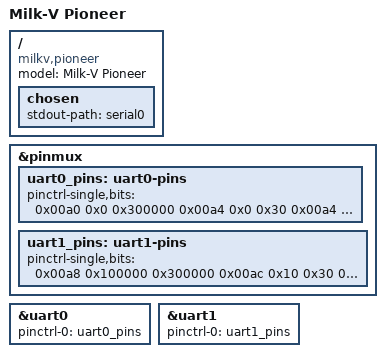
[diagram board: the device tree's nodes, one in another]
// SPDX-License-Identifier: GPL-2.0 OR MIT
/*
 * Copyright (C) 2022 Sophgo Technology Inc. All rights reserved.
 */

#include "sg2042.dtsi"

/ {
	model = "Milk-V Pioneer";
	compatible = "milkv,pioneer", "sophgo,sg2042";

	chosen {
		stdout-path = "serial0";
	};
};

&pinmux {
	status = "okay";

	uart0_pins: uart0-pins {
		pinctrl-single,bits = <
			/* UART0_TX */
			0x00a0 0x0 0x300000
			/* UART0_RX */
			0x00a4 0x0 0x30
			/* UART0_RTS */
			0x00a4 0x0 0x300000
			/* UART0_CTS */
			0x00a8 0x0 0x30
		>;
	};

	uart1_pins: uart1-pins {
		pinctrl-single,bits = <
			/* UART1_TX */
			0x00a8 0x100000 0x300000
			/* UART1_RX */
			0x00ac 0x10 0x30
			/* UART1_RTS */
			0x00ac 0x100000 0x300000
			/* UART1_CTS */
			0x00b0 0x10 0x30
		>;
	};
};

&uart0 {
	status = "okay";

	pinctrl-names = "default";
	pinctrl-0 = <&uart0_pins>;
};

&uart1 {
	status = "okay";

	pinctrl-names = "default";
	pinctrl-0 = <&uart1_pins>;
};
